VERSION ""

NS_ :

BS_:

BU_:

BO_ 768 HEARTBEAT: 8 Vector__XXX
 SG_ State : 0|8@1+ (1,0) [0|0] "" Vector__XXX
 SG_ Counter : 8|8@1+ (1,0) [0|0] "" Vector__XXX

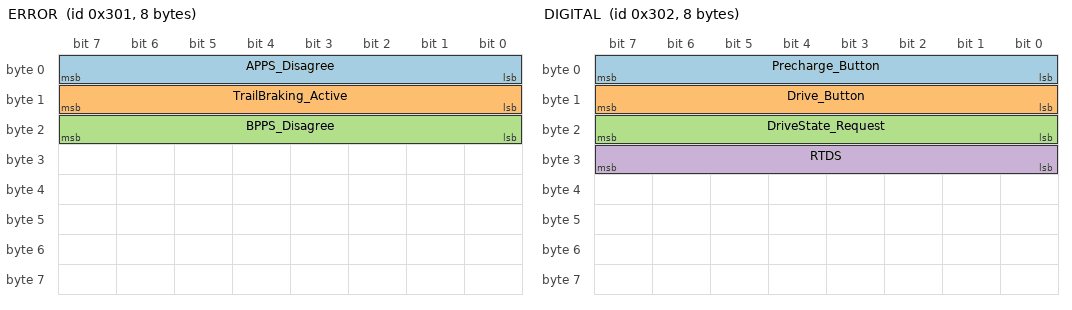
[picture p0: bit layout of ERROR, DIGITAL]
BO_ 769 ERROR: 8 Vector__XXX
 SG_ APPS_Disagree : 0|8@1+ (1,0) [0|0] "" Vector__XXX
 SG_ TrailBraking_Active : 8|8@1+ (1,0) [0|0] "" Vector__XXX
 SG_ BPPS_Disagree : 16|8@1+ (1,0) [0|0] "" Vector__XXX

BO_ 770 DIGITAL: 8 Vector__XXX
 SG_ Precharge_Button : 0|8@1+ (1,0) [0|0] "" Vector__XXX
 SG_ Drive_Button : 8|8@1+ (1,0) [0|0] "" Vector__XXX
 SG_ DriveState_Request : 16|8@1+ (1,0) [0|0] "" Vector__XXX
 SG_ RTDS : 24|8@1+ (1,0) [0|0] "" Vector__XXX

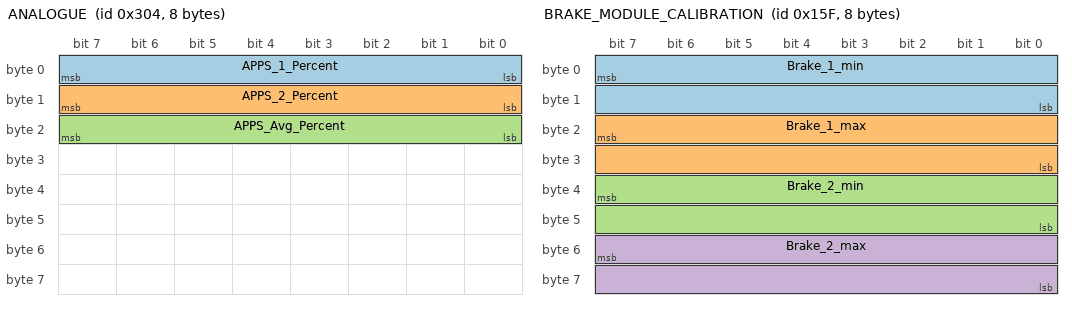
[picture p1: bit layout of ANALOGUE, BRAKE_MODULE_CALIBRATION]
BO_ 772 ANALOGUE: 8 Vector__XXX
 SG_ APPS_1_Percent : 0|8@1+ (1,0) [0|0] "%" Vector__XXX
 SG_ APPS_2_Percent : 8|8@1+ (1,0) [0|0] "%" Vector__XXX
 SG_ APPS_Avg_Percent : 16|8@1+ (1,0) [0|0] "%" Vector__XXX

BO_ 351 BRAKE_MODULE_CALIBRATION: 8 Vector__XXX
 SG_ Brake_1_min : 7|16@0+ (1,0) [0|0] "" Vector__XXX
 SG_ Brake_1_max : 23|16@0+ (1,0) [0|0] "" Vector__XXX
 SG_ Brake_2_min : 39|16@0+ (1,0) [0|0] "" Vector__XXX
 SG_ Brake_2_max : 55|16@0+ (1,0) [0|0] "" Vector__XXX

BO_ 595 RMS_COMMAND_MESSAGE: 8 Vector__XXX
